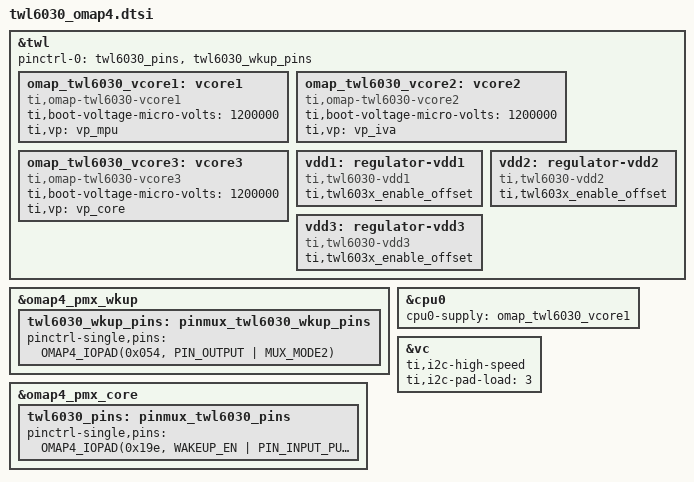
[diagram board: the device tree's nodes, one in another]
/*
 * Copyright (C) 2013 Texas Instruments Incorporated - http://www.ti.com/
 *
 * This program is free software; you can redistribute it and/or modify
 * it under the terms of the GNU General Public License version 2 as
 * published by the Free Software Foundation.
 */

&twl {
	/*
	 * On most OMAP4 platforms, the twl6030 IRQ line is connected
	 * to the SYS_NIRQ1 line on OMAP and the twl6030 MSECURE line is
	 * connected to the fref_clk0_out.sys_drm_msecure line.
	 * Therefore, configure the defaults for the SYS_NIRQ1 and
	 * fref_clk0_out.sys_drm_msecure pins here.
	 */
	pinctrl-names = "default";
	pinctrl-0 = <
		&twl6030_pins
		&twl6030_wkup_pins
	>;

	omap_twl6030_vcore1: vcore1 {
		compatible = "ti,omap-twl6030-vcore1";
		ti,boot-voltage-micro-volts = <1200000>;
		ti,vp = <&vp_mpu>;
	};

	omap_twl6030_vcore2: vcore2 {
		compatible = "ti,omap-twl6030-vcore2";
		ti,boot-voltage-micro-volts = <1200000>;
		ti,vp = <&vp_iva>;
	};

	omap_twl6030_vcore3: vcore3 {
		compatible = "ti,omap-twl6030-vcore3";
		ti,boot-voltage-micro-volts = <1200000>;
		ti,vp = <&vp_core>;
	};

	vdd1: regulator-vdd1 {
		compatible = "ti,twl6030-vdd1";
		ti,twl603x_enable_offset;
	};

	vdd2: regulator-vdd2 {
		compatible = "ti,twl6030-vdd2";
		ti,twl603x_enable_offset;
	};

	vdd3: regulator-vdd3 {
		compatible = "ti,twl6030-vdd3";
		ti,twl603x_enable_offset;
	};
};

&omap4_pmx_wkup {
	twl6030_wkup_pins: pinmux_twl6030_wkup_pins {
		pinctrl-single,pins = <
			OMAP4_IOPAD(0x054, PIN_OUTPUT | MUX_MODE2)		/* fref_clk0_out.sys_drm_msecure */
		>;
	};
};

&omap4_pmx_core {
	twl6030_pins: pinmux_twl6030_pins {
		pinctrl-single,pins = <
			OMAP4_IOPAD(0x19e, WAKEUP_EN | PIN_INPUT_PULLUP | MUX_MODE0)	/* sys_nirq1.sys_nirq1 */
		>;
	};
};

&cpu0 {
	cpu0-supply = <&omap_twl6030_vcore1>;
};

&vc {
	ti,i2c-high-speed;
	ti,i2c-pad-load = <3>;
};
